# ESP32-S2-ULP register map
Vendor: ESPRESSIF SYSTEMS (SHANGHAI) CO., LTD.; Series: RISC-V ULP; File version: 2
32-bit RISC-V MCU
CPU: RV32IMC r0p0, little endian, no MPU, no FPU, 0 interrupt priority bits
Address unit: 32 bits
Registers are 32-bit, read-write, reset 0x0 unless marked. A register's access mark holds for its fields unless they carry their own. Offsets are from the block's base; lines under a group give offsets from that group; [hi:lo] are bit positions; {n}, {i} and the like mark numbered series; 'fields as' and 'values as' point back to an identical list; <NAME> marks a mode.

## Memory map
0x00008000 RTC_CNTL size 0x138 — Real-Time Clock Control
0x0000A400 RTC_IO size 0xF0 — Low-power Input/Output
0x0000C800 SENS size 0x110 — SENS Peripheral
0x0000EC00 RTC_I2C size 0x7C — Low-power I2C (Inter-Integrated Circuit) Controller

## Interrupts
0 TOUCH_DONE_INT (SENS)
1 TOUCH_INACTIVE_INT (SENS)
2 TOUCH_ACTIVE_INT (SENS)
3 SARADC1_DONE_INT (SENS)
4 SARADC2_DONE_INT (SENS)
5 TSENS_DONE_INT (SENS)
6 RISCV_START_INT (RTC_CNTL)
7 SW_INT (RTC_CNTL)
8 SWD_INT (RTC_CNTL)
9 GPIO_INT (RTC_IO)

## RTC_I2C — Low-power I2C (Inter-Integrated Circuit) Controller
Base 0x0000EC00
0x00 SCL_LOW reset 0x100 — Configure the low level width of SCL
  [19:0] PERIOD — This register is used to configure how many clock cycles SCL remains low.
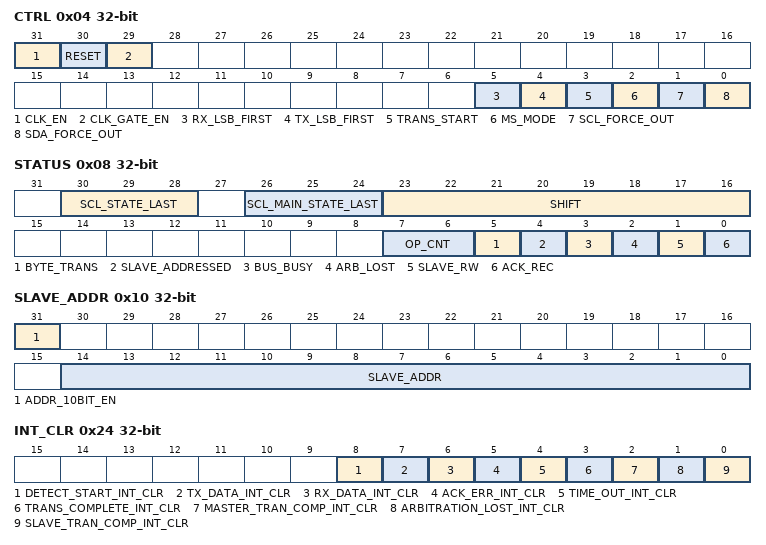
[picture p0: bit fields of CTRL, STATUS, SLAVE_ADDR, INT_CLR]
0x04 CTRL — Transmission setting
  [31] CLK_EN — rtc i2c reg clk gating
  [30] RESET — RTC I²C software reset.
  [29] CLK_GATE_EN — RTC I²C controller clock gate.
  [5] RX_LSB_FIRST — This bit is used to control the storage mode for received data. 0: receive data from the most significant bit. 1: receive data from the least significant bit.
  [4] TX_LSB_FIRST — This bit is used to control the sending mode. 0: send data from the most significant bit. 1: send data from the least significant bit.
  [3] TRANS_START — Set this bit to 1, RTC I2C starts sending data.
  [2] MS_MODE — Set this bit to configure RTC I²C as a master.
  [1] SCL_FORCE_OUT — SCL output mode. 0: open drain. 1: push pull.
  [0] SDA_FORCE_OUT — SDA output mode. 0: open drain. 1: push pull.
0x08 STATUS ro — RTC I2C status
  [30:28] SCL_STATE_LAST — scl last status
  [26:24] SCL_MAIN_STATE_LAST — i2c last main status
  [23:16] SHIFT — shifter content
  [7:6] OP_CNT — Indicate which operation is working.
  [5] BYTE_TRANS — This field changes to 1 when one byte is transferred.
  [4] SLAVE_ADDRESSED — When the address sent by the master matches the address of the slave, then this bit will be set.
  [3] BUS_BUSY — 0: RTC I2C bus is in idle state. 1: RTC I2C bus is busy transferring data.
  [2] ARB_LOST — When the RTC I2C loses control of SCL line, the register changes to 1.
  [1] SLAVE_RW — 0: master writes to slave. 1: master reads from slave.
  [0] ACK_REC — The received ACK value. 0: ACK. 1: NACK.
0x0C TO reset 0x10000 — Configure RTC I2C timeout
  [19:0] TIME_OUT — Timeout threshold
0x10 SLAVE_ADDR — Configure slave address
  [31] ADDR_10BIT_EN — This field is used to enable the slave 10-bit addressing mode.
  [14:0] SLAVE_ADDR — slave address
0x14 SCL_HIGH reset 0x100 — Configure the high level width of SCL
  [19:0] PERIOD — This register is used to configure how many cycles SCL remains high.
0x18 SDA_DUTY reset 0x10 — Configure the SDA hold time after a negative SCL edge
  [19:0] NUM — The number of clock cycles between the SDA switch and the falling edge of SCL.
0x1C SCL_START_PERIOD reset 0x8 — Configure the delay between the SDA and SCL negative edge for a start condition
  [19:0] SCL_START_PERIOD — Number of clock cycles to wait after generating a start condition.
0x20 SCL_STOP_PERIOD reset 0x8 — Configure the delay between SDA and SCL positive edge for a stop condition
  [19:0] SCL_STOP_PERIOD — Number of clock cycles to wait before generating a stop condition.
0x24 INT_CLR wo — Clear RTC I2C interrupt
  [8] DETECT_START_INT_CLR — RTC_I2C_DETECT_START_INT interrupt clear bit
  [7] TX_DATA_INT_CLR — RTC_I2C_TX_DATA_INT interrupt clear bit
  [6] RX_DATA_INT_CLR — RTC_I2C_RX_DATA_INT interrupt clear bit
  [5] ACK_ERR_INT_CLR — RTC_I2C_ACK_ERR_INT interrupt clear bit
  [4] TIME_OUT_INT_CLR — RTC_I2C_TIME_OUT_INT interrupt clear bit
  [3] TRANS_COMPLETE_INT_CLR — RTC_I2C_TRANS_COMPLETE_INT interrupt clear bit
  [2] MASTER_TRAN_COMP_INT_CLR — RTC_I2C_MASTER_TRAN_COMP_INT interrupt clear bit
  [1] ARBITRATION_LOST_INT_CLR — RTC_I2C_ARBITRATION_LOST_INT interrupt clear bit
  [0] SLAVE_TRAN_COMP_INT_CLR — RTC_I2C_SLAVE_TRAN_COMP_INT interrupt clear bit
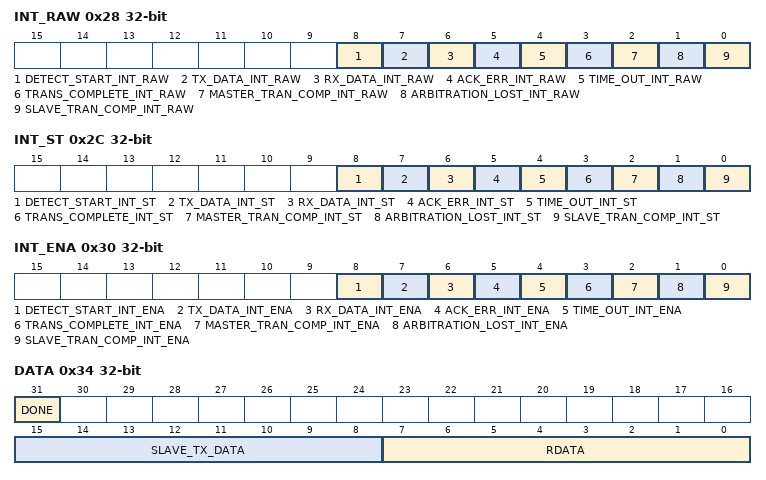
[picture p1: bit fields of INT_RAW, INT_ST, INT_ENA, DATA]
0x28 INT_RAW ro — RTC I2C raw interrupt
  [8] DETECT_START_INT_RAW — RTC_I2C_DETECT_START_INT interrupt raw bit
  [7] TX_DATA_INT_RAW — RTC_I2C_TX_DATA_INT interrupt raw bit
  [6] RX_DATA_INT_RAW — RTC_I2C_RX_DATA_INT interrupt raw bit
  [5] ACK_ERR_INT_RAW — RTC_I2C_ACK_ERR_INT interrupt raw bit
  [4] TIME_OUT_INT_RAW — RTC_I2C_TIME_OUT_INT interrupt raw bit
  [3] TRANS_COMPLETE_INT_RAW — RTC_I2C_TRANS_COMPLETE_INT interrupt raw bit
  [2] MASTER_TRAN_COMP_INT_RAW — RTC_I2C_MASTER_TRAN_COMP_INT interrupt raw bit
  [1] ARBITRATION_LOST_INT_RAW — RTC_I2C_ARBITRATION_LOST_INT interrupt raw bit
  [0] SLAVE_TRAN_COMP_INT_RAW — RTC_I2C_SLAVE_TRAN_COMP_INT interrupt raw bit
0x2C INT_ST ro — RTC I2C interrupt status
  [8] DETECT_START_INT_ST — RTC_I2C_DETECT_START_INT interrupt status bit
  [7] TX_DATA_INT_ST — RTC_I2C_TX_DATA_INT interrupt status bit
  [6] RX_DATA_INT_ST — RTC_I2C_RX_DATA_INT interrupt status bit
  [5] ACK_ERR_INT_ST — RTC_I2C_ACK_ERR_INT interrupt status bit
  [4] TIME_OUT_INT_ST — RTC_I2C_TIME_OUT_INT interrupt status bit
  [3] TRANS_COMPLETE_INT_ST — RTC_I2C_TRANS_COMPLETE_INT interrupt status bit
  [2] MASTER_TRAN_COMP_INT_ST — RTC_I2C_MASTER_TRAN_COMP_INT interrupt status bit
  [1] ARBITRATION_LOST_INT_ST — RTC_I2C_ARBITRATION_LOST_INT interrupt status bit
  [0] SLAVE_TRAN_COMP_INT_ST — RTC_I2C_SLAVE_TRAN_COMP_INT interrupt status bit
0x30 INT_ENA — Enable RTC I2C interrupt
  [8] DETECT_START_INT_ENA — RTC_I2C_DETECT_START_INT interrupt enable bit
  [7] TX_DATA_INT_ENA — RTC_I2C_TX_DATA_INT interrupt enable bit
  [6] RX_DATA_INT_ENA — RTC_I2C_RX_DATA_INT interrupt enable bit
  [5] ACK_ERR_INT_ENA — RTC_I2C_ACK_ERR_INT interrupt enable bit
  [4] TIME_OUT_INT_ENA — RTC_I2C_TIME_OUT_INT interrupt enable bit
  [3] TRANS_COMPLETE_INT_ENA — RTC_I2C_TRANS_COMPLETE_INT interrupt enable bit
  [2] MASTER_TRAN_COMP_INT_ENA — RTC_I2C_MASTER_TRAN_COMP_INT interrupt enable bit
  [1] ARBITRATION_LOST_INT_ENA — RTC_I2C_ARBITRATION_LOST_INT interrupt enable bit
  [0] SLAVE_TRAN_COMP_INT_ENA — RTC_I2C_SLAVE_TRAN_COMP_INT interrupt enable bit
0x34 DATA access per field — RTC I2C read data
  [31] DONE ro — RTC I2C transmission is done.
  [15:8] SLAVE_TX_DATA rw — The data sent by slave
  [7:0] RDATA ro — Data received
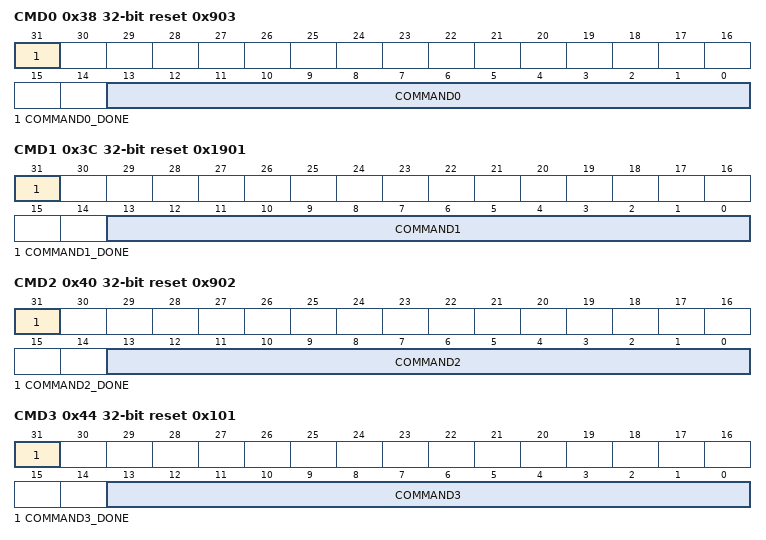
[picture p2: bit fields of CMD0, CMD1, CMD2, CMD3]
0x38 CMD0 access per field reset 0x903 — RTC I2C Command 0
  [31] COMMAND0_DONE ro — When command 0 is done, this bit changes to 1.
  [13:0] COMMAND0 rw — Content of command 0. For more information, please refer to the register I2C_COMD0_REG in Chapter I²C Controller
0x3C CMD1 access per field reset 0x1901 — RTC I2C Command 1
  [31] COMMAND1_DONE ro — When command 1 is done, this bit changes to 1.
  [13:0] COMMAND1 rw — Content of command 1. For more information, please refer to the register I2C_COMD1_REG in Chapter I²C Controller.
0x40 CMD2 access per field reset 0x902 — RTC I2C Command 2
  [31] COMMAND2_DONE ro — When command 2 is done, this bit changes to 1.
  [13:0] COMMAND2 rw — Content of command 2. For more information, please refer to the register I2C_COMD2_REG in Chapter I²C Controller.
0x44 CMD3 access per field reset 0x101 — RTC I2C Command 3
  [31] COMMAND3_DONE ro — When command 3 is done, this bit changes to 1.
  [13:0] COMMAND3 rw — Content of command 3. For more information, please refer to the register I2C_COMD3_REG in Chapter I²C Controller.
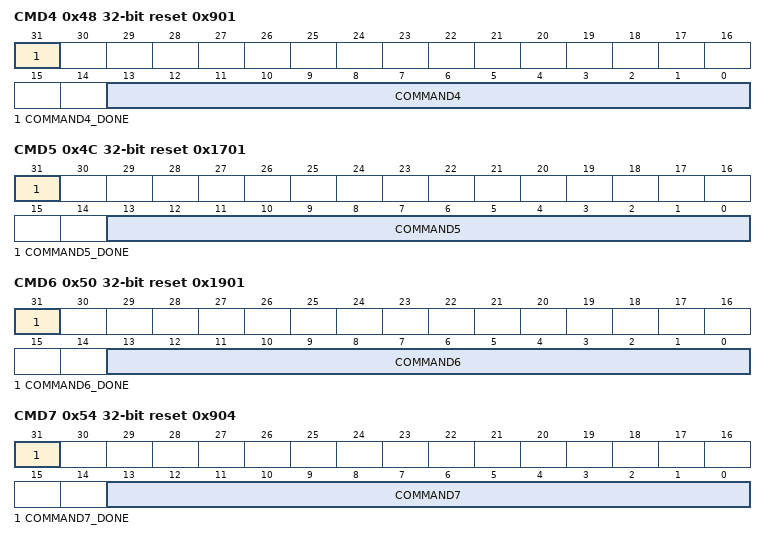
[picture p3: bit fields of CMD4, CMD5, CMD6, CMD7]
0x48 CMD4 access per field reset 0x901 — RTC I2C Command 4
  [31] COMMAND4_DONE ro — When command 4 is done, this bit changes to 1.
  [13:0] COMMAND4 rw — Content of command 4. For more information, please refer to the register I2C_COMD4_REG in Chapter I²C Controller.
0x4C CMD5 access per field reset 0x1701 — RTC I2C Command 5
  [31] COMMAND5_DONE ro — When command 5 is done, this bit changes to 1.
  [13:0] COMMAND5 rw — Content of command 5. For more information, please refer to the register I2C_COMD5_REG in Chapter I²C Controller.
0x50 CMD6 access per field reset 0x1901 — RTC I2C Command 6
  [31] COMMAND6_DONE ro — When command 6 is done, this bit changes to 1.
  [13:0] COMMAND6 rw — Content of command 6. For more information, please refer to the register I2C_COMD6_REG in Chapter I²C Controller.
0x54 CMD7 access per field reset 0x904 — RTC I2C Command 7
  [31] COMMAND7_DONE ro — When command 7 is done, this bit changes to 1.
  [13:0] COMMAND7 rw — Content of command 7. For more information, please refer to the register I2C_COMD7_REG in Chapter I²C Controller.
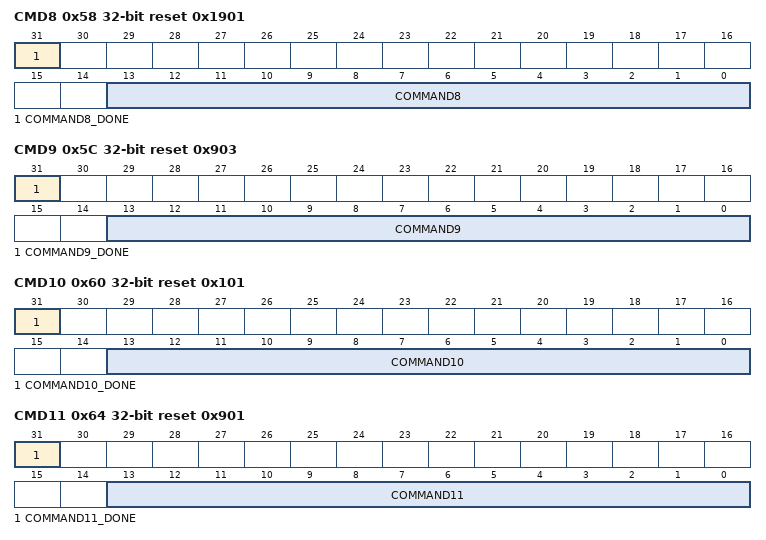
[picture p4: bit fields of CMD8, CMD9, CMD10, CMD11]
0x58 CMD8 access per field reset 0x1901 — RTC I2C Command 8
  [31] COMMAND8_DONE ro — When command 8 is done, this bit changes to 1.
  [13:0] COMMAND8 rw — Content of command 8. For more information, please refer to the register I2C_COMD8_REG in Chapter I²C Controller.
0x5C CMD9 access per field reset 0x903 — RTC I2C Command 9
  [31] COMMAND9_DONE ro — When command 9 is done, this bit changes to 1.
  [13:0] COMMAND9 rw — Content of command 9. For more information, please refer to the register I2C_COMD9_REG in Chapter I²C Controller
0x60 CMD10 access per field reset 0x101 — RTC I2C Command 10
  [31] COMMAND10_DONE ro — When command 10 is done, this bit changes to 1.
  [13:0] COMMAND10 rw — Content of command 10. For more information, please refer to the register I2C_COMD10_REG in Chapter I²C Controller.
0x64 CMD11 access per field reset 0x901 — RTC I2C Command 11
  [31] COMMAND11_DONE ro — When command 11 is done, this bit changes to 1.
  [13:0] COMMAND11 rw — Content of command 11. For more information, please refer to the register I2C_COMD11_REG in Chapter I²C Controller.
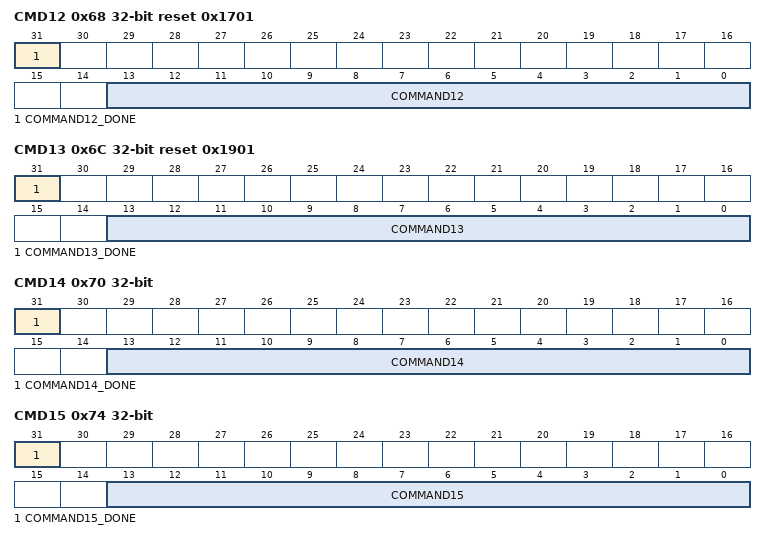
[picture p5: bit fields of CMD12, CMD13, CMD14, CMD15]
0x68 CMD12 access per field reset 0x1701 — RTC I2C Command 12
  [31] COMMAND12_DONE ro — When command 12 is done, this bit changes to 1.
  [13:0] COMMAND12 rw — Content of command 12. For more information, please refer to the register I2C_COMD12_REG in Chapter I²C Controller.
0x6C CMD13 access per field reset 0x1901 — RTC I2C Command 13
  [31] COMMAND13_DONE ro — When command 13 is done, this bit changes to 1.
  [13:0] COMMAND13 rw — Content of command 13. For more information, please refer to the register I2C_COMD13_REG in Chapter I²C Controller.
0x70 CMD14 access per field — RTC I2C Command 14
  [31] COMMAND14_DONE ro — When command 14 is done, this bit changes to 1.
  [13:0] COMMAND14 rw — Content of command 14. For more information, please refer to the register I2C_COMD14_REG in Chapter I²C Controller.
0x74 CMD15 access per field — RTC I2C Command 15
  [31] COMMAND15_DONE ro — When command 15 is done, this bit changes to 1.
  [13:0] COMMAND15 rw — Content of command 15. For more information, please refer to the register I2C_COMD15_REG in Chapter I²C Controller.
0xFC DATE reset 0x1905310 — Version control register
  [27:0] DATE

## Licence text in the file
Copyright 2025 Espressif Systems (Shanghai) PTE LTD Licensed under the Apache License, Version 2.0 (the "License"); you may not use this file except in compliance with the License. You may obtain a copy of the License at http://www.apache.org/licenses/LICENSE-2.0 Unless required by applicable law or agreed to in writing, software distributed under the License is distributed on an "AS IS" BASIS, WITHOUT WARRANTIES OR CONDITIONS OF ANY KIND, either express or implied. See the License for the specific language governing permissions and limitations under the License.
